# STM32U5Fx register map
File version: 1.0
CPU: CM33 r0p1, little endian, MPU, FPU, 4 interrupt priority bits
Registers are 32-bit, read-write, reset 0x0 unless marked. A register's access mark holds for its fields unless they carry their own. Offsets are from the block's base; [hi:lo] are bit positions; {n}, {i} and the like mark numbered series.

## CORDIC — CORDIC Co-processor
Base 0x40021000
Same registers: SEC_CORDIC 0x50021000
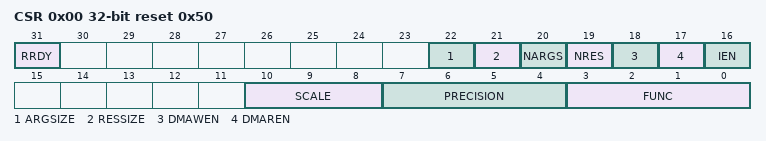
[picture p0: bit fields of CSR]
0x00 CSR access per field reset 0x50 — CORDIC Control Status register
  [31] RRDY ro — Result ready flag
  [22] ARGSIZE rw — Width of input data
  [21] RESSIZE rw — Width of output data
  [20] NARGS rw — Number of arguments expected by the CORDIC_WDATA register
  [19] NRES rw — Number of results in the CORDIC_RDATA register
  [18] DMAWEN rw — Enable DMA write channel
  [17] DMAREN rw — Enable DMA read channel
  [16] IEN rw — Enable interrupt
  [10:8] SCALE rw — Scaling factor
  [7:4] PRECISION rw — Precision required (number of iterations)
  [3:0] FUNC rw — Function
0x04 WDATA wo — FMAC Write Data register
  [31:0] ARG — Function input arguments
0x08 RDATA ro — FMAC Read Data register
  [31:0] RES — Function result

## CRC — Cyclic redundancy check calculation unit
Base 0x40023000
Same registers: SEC_CRC 0x50023000
0x00 DR reset 0xFFFFFFFF — Data register
  [31:0] DR — Data register bits
0x04 IDR — Independent data register
  [31:0] IDR — General-purpose 8-bit data register bits
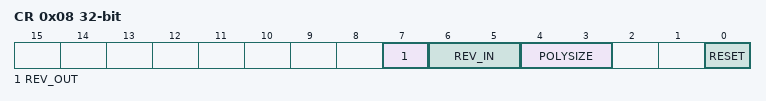
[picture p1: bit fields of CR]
0x08 CR — Control register
  [7] REV_OUT — Reverse output data
  [6:5] REV_IN — Reverse input data
  [4:3] POLYSIZE — Polynomial size
  [0] RESET — RESET bit
0x10 INIT reset 0xFFFFFFFF — Initial CRC value
  [31:0] CRC_INIT — Programmable initial CRC value
0x14 POL reset 0x4C11DB7 — polynomial
  [31:0] POL — Programmable polynomial

## CRS — Clock recovery system
Base 0x40006000
Same registers: SEC_CRS 0x50006000
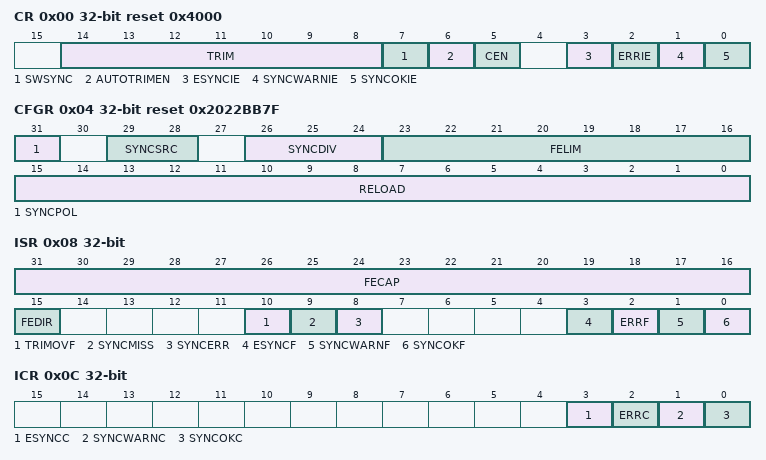
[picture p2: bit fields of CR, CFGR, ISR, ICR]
0x00 CR reset 0x4000 — control register
  [14:8] TRIM — HSI48 oscillator smooth trimming
  [7] SWSYNC — Generate software SYNC event
  [6] AUTOTRIMEN — Automatic trimming enable
  [5] CEN — Frequency error counter enable
  [3] ESYNCIE — Expected SYNC interrupt enable
  [2] ERRIE — Synchronization or trimming error interrupt enable
  [1] SYNCWARNIE — SYNC warning interrupt enable
  [0] SYNCOKIE — SYNC event OK interrupt enable
0x04 CFGR reset 0x2022BB7F — configuration register
  [31] SYNCPOL — SYNC polarity selection
  [29:28] SYNCSRC — SYNC signal source selection
  [26:24] SYNCDIV — SYNC divider
  [23:16] FELIM — Frequency error limit
  [15:0] RELOAD — Counter reload value
0x08 ISR ro — interrupt and status register
  [31:16] FECAP — Frequency error capture
  [15] FEDIR — Frequency error direction
  [10] TRIMOVF — Trimming overflow or underflow
  [9] SYNCMISS — SYNC missed
  [8] SYNCERR — SYNC error
  [3] ESYNCF — Expected SYNC flag
  [2] ERRF — Error flag
  [1] SYNCWARNF — SYNC warning flag
  [0] SYNCOKF — SYNC event OK flag
0x0C ICR — interrupt flag clear register
  [3] ESYNCC — Expected SYNC clear flag
  [2] ERRC — Error clear flag
  [1] SYNCWARNC — SYNC warning clear flag
  [0] SYNCOKC — SYNC event OK clear flag

## DBGMCU — MCU debug component
Base 0xE0044000
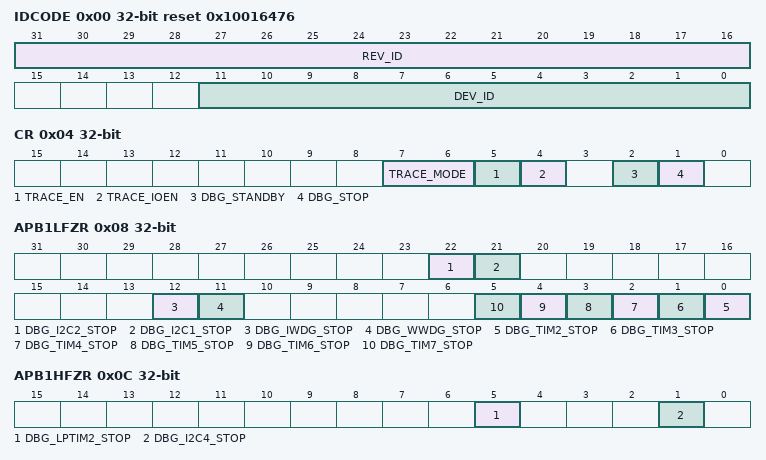
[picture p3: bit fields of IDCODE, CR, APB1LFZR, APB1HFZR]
0x00 IDCODE ro reset 0x10016476 — DBGMCU_IDCODE
  [31:16] REV_ID — Revision
  [11:0] DEV_ID — Device dentification
0x04 CR — Debug MCU configuration register
  [7:6] TRACE_MODE — Trace pin assignment control
  [5] TRACE_EN — trace port and clock enable
  [4] TRACE_IOEN — Trace pin assignment control
  [2] DBG_STANDBY — Debug Standby mode
  [1] DBG_STOP — Debug Stop mode
0x08 APB1LFZR — Debug MCU APB1L peripheral freeze register
  [22] DBG_I2C2_STOP — I2C2 SMBUS timeout stop in debug
  [21] DBG_I2C1_STOP — I2C1 SMBUS timeout stop in debug
  [12] DBG_IWDG_STOP — Independent watchdog counter stop in debug
  [11] DBG_WWDG_STOP — Window watchdog counter stop in debug
  [n-2] DBG_TIM{n}_STOP (n=2..7) — TIM{n} stop in debug
0x0C APB1HFZR — Debug MCU APB1H peripheral freeze register
  [5] DBG_LPTIM2_STOP — LPTIM2 stop in debug
  [1] DBG_I2C4_STOP — I2C4 stop in debug
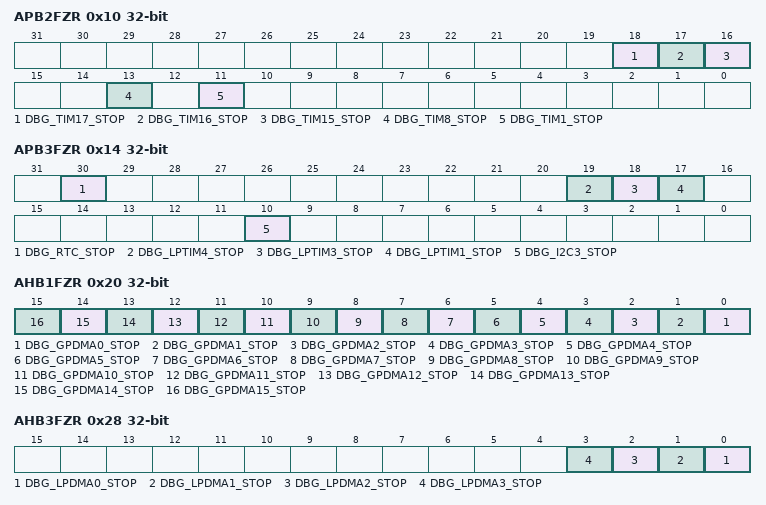
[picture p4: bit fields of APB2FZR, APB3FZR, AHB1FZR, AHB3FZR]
0x10 APB2FZR — Debug MCU APB2 peripheral freeze register
  [18] DBG_TIM17_STOP
  [17] DBG_TIM16_STOP — TIM16 counter stopped when core is halted
  [16] DBG_TIM15_STOP — TIM15 counter stopped when core is halted
  [13] DBG_TIM8_STOP — TIM8 stop in debug
  [11] DBG_TIM1_STOP — TIM1 counter stopped when core is halted
0x14 APB3FZR — Debug MCU APB3 peripheral freeze register
  [30] DBG_RTC_STOP — RTC stop in debug
  [19] DBG_LPTIM4_STOP — LPTIM4 stop in debug
  [18] DBG_LPTIM3_STOP — LPTIM3 stop in debug
  [17] DBG_LPTIM1_STOP — LPTIM1 stop in debug
  [10] DBG_I2C3_STOP — I2C3 stop in debug
0x20 AHB1FZR — Debug MCU AHB1 peripheral freeze register
  [n] DBG_GPDMA{n}_STOP (n=0..15) — GPDMA channel {n} stop in debug
0x28 AHB3FZR — Debug MCU AHB3 peripheral freeze register
  [n] DBG_LPDMA{n}_STOP (n=0..3) — LPDMA channel {n} stop in debug
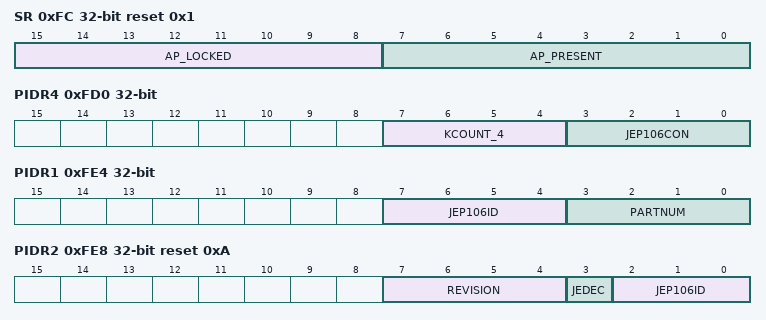
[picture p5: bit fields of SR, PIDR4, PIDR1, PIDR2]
0xFC SR ro reset 0x1 — DBGMCU status register
  [15:8] AP_LOCKED, [7:0] AP_PRESENT
0x100 DBGMCU_DBG_AUTH_HOST ro — DBGMCU debug host authentication register
  [31:0] AUTH_KEY
0x104 DBG_AUTH_DEVICE ro — DBGMCU debug device authentication register
  [15:0] AUTH_ID
0xFD0 PIDR4 ro — Debug MCU CoreSight peripheral identity register 4
  [7:4] KCOUNT_4 — register file size
  [3:0] JEP106CON — JEP106 continuation code
0xFE0 PIDR0 ro — Debug MCU CoreSight peripheral identity register 0
  [7:0] PARTNUM — part number bits [7:0]
0xFE4 PIDR1 ro — Debug MCU CoreSight peripheral identity register 1
  [7:4] JEP106ID — JEP106 identity code bits [3:0]
  [3:0] PARTNUM — part number bits [11:8]
0xFE8 PIDR2 ro reset 0xA — Debug MCU CoreSight peripheral identity register 2
  [7:4] REVISION — component revision number
  [3] JEDEC — JEDEC assigned value
  [2:0] JEP106ID — JEP106 identity code bits [6:4]
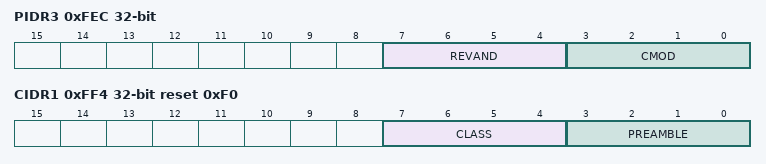
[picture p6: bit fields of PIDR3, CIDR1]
0xFEC PIDR3 ro — Debug MCU CoreSight peripheral identity register 3
  [7:4] REVAND — metal fix version
  [3:0] CMOD — customer modified
0xFF0 CIDR0 ro reset 0xD — Debug MCU CoreSight component identity register 0
  [7:0] PREAMBLE — component identification bits [7:0]
0xFF4 CIDR1 ro reset 0xF0 — Debug MCU CoreSight component identity register 1
  [7:4] CLASS — component identification bits [15:12] - component class
  [3:0] PREAMBLE — component identification bits [11:8]
0xFF8 CIDR2 ro reset 0x5 — Debug MCU CoreSight component identity register 2
  [7:0] PREAMBLE — component identification bits [23:16]
0xFFC CIDR3 ro reset 0xB1 — Debug MCU CoreSight component identity register 3
  [7:0] PREAMBLE — component identification bits [31:24]
